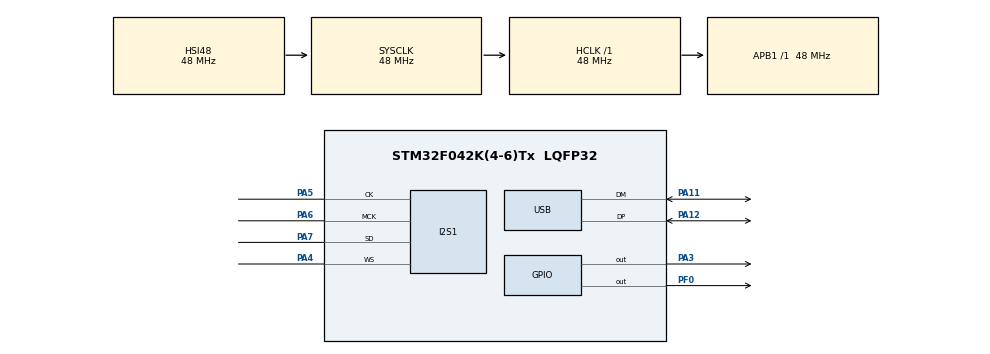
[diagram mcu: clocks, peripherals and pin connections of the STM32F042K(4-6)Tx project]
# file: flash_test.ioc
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I2S1.AudioFreq=I2S_AUDIOFREQ_48K
I2S1.DataFormat=I2S_DATAFORMAT_24B
I2S1.ErrorAudioFreq=-2.34 %
I2S1.FullDuplexMode=I2S_FULLDUPLEXMODE_DISABLE
I2S1.Instance=SPI$Index
I2S1.MCLKOutput=I2S_MCLKOUTPUT_ENABLE
I2S1.RealAudioFreq=46.875 KHz
I2S1.VirtualMode=I2S_MODE_MASTER
Mcu.Family=STM32F0
Mcu.Name=STM32F042K(4-6)Tx
Mcu.Package=LQFP32
PA11.Mode=Device
PA11.Signal=USB_DM
PA12.Mode=Device
PA12.Signal=USB_DP
PA3.Signal=GPIO_Output
PA4.Mode=Half_Duplex_Master
PA4.Signal=I2S1_WS
PA5.Mode=Half_Duplex_Master
PA5.Signal=I2S1_CK
PA6.Mode=Master_Clock_Activated
PA6.Signal=I2S1_MCK
PA7.Mode=Half_Duplex_Master
PA7.Signal=I2S1_SD
PF0-OSC_IN.Signal=GPIO_Output
ProjectManager.HeapSize=0x200
ProjectManager.StackSize=0x400
ProjectManager.TargetToolchain=STM32CubeIDE
RCC.AHBFreq_Value=48000000
RCC.APB1Freq_Value=48000000
RCC.APB1TimFreq_Value=48000000
RCC.HCLKFreq_Value=48000000
RCC.SYSCLKFreq_VALUE=48000000
RCC.SYSCLKSource=RCC_SYSCLKSOURCE_HSI48
board=custom

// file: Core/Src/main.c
/* USER CODE BEGIN Header */
/**
  ******************************************************************************
  * @file           : main.c
  * @brief          : Main program body
  ******************************************************************************
  * @attention
  *
  * Copyright (c) 2022 STMicroelectronics.
  * All rights reserved.
  *
  * This software is licensed under terms that can be found in the LICENSE file
  * in the root directory of this software component.
  * If no LICENSE file comes with this software, it is provided AS-IS.
  *
  ******************************************************************************
  */
/* USER CODE END Header */
#include "main.h"

/* USER CODE BEGIN Includes */
#include "usb_audio.h"
/* USER CODE END Includes */

 I2S_HandleTypeDef hi2s1;

PCD_HandleTypeDef hpcd_USB_FS;

void SystemClock_Config(void);
static void MX_GPIO_Init(void);
static void MX_I2S1_Init(void);
static void MX_USB_PCD_Init(void);

/* USER CODE BEGIN 0 */

/* Private variables ---------------------------------------------------------*/
USBD_HandleTypeDef USBD_Device;
#if USE_AUDIO_TIMER_VOLUME_CTRL
TIM_HandleTypeDef    TimHandle;
/* Prescaler declaration */
uint32_t uwPrescalerValue = 0;
#endif /* USE_AUDIO_TIMER_VOLUME_CTRL */
/* Private function prototypes -----------------------------------------------*/

#if USE_AUDIO_TIMER_VOLUME_CTRL
static HAL_StatusTypeDef Timer_Init(void);
#endif /* USE_AUDIO_TIMER_VOLUME_CTRL */
/* externals  variables -----------------------------------------------*/
extern USBD_AUDIO_InterfaceCallbacksfTypeDef audio_class_interface;

/* USER CODE END 0 */

int main(void)
{

  /* MCU Configuration--------------------------------------------------------*/

  /* Reset of all peripherals, Initializes the Flash interface and the Systick. */
  HAL_Init();

  /* Configure the system clock */
  SystemClock_Config();

  /* Initialize all configured peripherals */
  MX_GPIO_Init();
  MX_I2S1_Init();
  MX_USB_PCD_Init();
  /* USER CODE BEGIN 2 */
  //bring ADC out of reset
  //HAL_GPIO_WritePin(GPIOA, GPIO_PIN_3, GPIO_PIN_SET);
  /* Init Device Library */
  USBD_Init(&USBD_Device, &AUDIO_Desc, 0);

  /* Add Supported Class */
  USBD_RegisterClass(&USBD_Device, USBD_AUDIO_CLASS);

  /* Add Interface callbacks for AUDIO Class */
  USBD_AUDIO_RegisterInterface(&USBD_Device, &audio_class_interface);

  /* Start Device Process */
  USBD_Start(&USBD_Device);
  /* USER CODE END 2 */

  /* Infinite loop */
  while (1)
  {

  }
}

void SystemClock_Config(void)
{
  RCC_OscInitTypeDef RCC_OscInitStruct = {0};
  RCC_ClkInitTypeDef RCC_ClkInitStruct = {0};
  RCC_PeriphCLKInitTypeDef PeriphClkInit = {0};

  /** Initializes the RCC Oscillators according to the specified parameters
  * in the RCC_OscInitTypeDef structure.
  */
  RCC_OscInitStruct.OscillatorType = RCC_OSCILLATORTYPE_HSI48;
  RCC_OscInitStruct.HSI48State = RCC_HSI48_ON;
  RCC_OscInitStruct.PLL.PLLState = RCC_PLL_NONE;
  if (HAL_RCC_OscConfig(&RCC_OscInitStruct) != HAL_OK)
  {
    Error_Handler();
  }

  /** Initializes the CPU, AHB and APB buses clocks
  */
  RCC_ClkInitStruct.ClockType = RCC_CLOCKTYPE_HCLK|RCC_CLOCKTYPE_SYSCLK
                              |RCC_CLOCKTYPE_PCLK1;
  RCC_ClkInitStruct.SYSCLKSource = RCC_SYSCLKSOURCE_HSI48;
  RCC_ClkInitStruct.AHBCLKDivider = RCC_SYSCLK_DIV1;
  RCC_ClkInitStruct.APB1CLKDivider = RCC_HCLK_DIV1;

  if (HAL_RCC_ClockConfig(&RCC_ClkInitStruct, FLASH_LATENCY_1) != HAL_OK)
  {
    Error_Handler();
  }
  PeriphClkInit.PeriphClockSelection = RCC_PERIPHCLK_USB;
  PeriphClkInit.UsbClockSelection = RCC_USBCLKSOURCE_HSI48;

  if (HAL_RCCEx_PeriphCLKConfig(&PeriphClkInit) != HAL_OK)
  {
    Error_Handler();
  }
}

static void MX_I2S1_Init(void)
{

  hi2s1.Instance = SPI1;
  hi2s1.Init.Mode = I2S_MODE_MASTER_TX;
  hi2s1.Init.Standard = I2S_STANDARD_PHILIPS;
  hi2s1.Init.DataFormat = I2S_DATAFORMAT_24B;
  hi2s1.Init.MCLKOutput = I2S_MCLKOUTPUT_ENABLE;
  hi2s1.Init.AudioFreq = I2S_AUDIOFREQ_48K;
  hi2s1.Init.CPOL = I2S_CPOL_LOW;
  if (HAL_I2S_Init(&hi2s1) != HAL_OK)
  {
    Error_Handler();
  }

}

static void MX_USB_PCD_Init(void)
{

  hpcd_USB_FS.Instance = USB;
  hpcd_USB_FS.Init.dev_endpoints = 8;
  hpcd_USB_FS.Init.speed = PCD_SPEED_FULL;
  hpcd_USB_FS.Init.phy_itface = PCD_PHY_EMBEDDED;
  hpcd_USB_FS.Init.low_power_enable = DISABLE;
  hpcd_USB_FS.Init.lpm_enable = DISABLE;
  hpcd_USB_FS.Init.battery_charging_enable = DISABLE;
  if (HAL_PCD_Init(&hpcd_USB_FS) != HAL_OK)
  {
    Error_Handler();
  }

}

static void MX_GPIO_Init(void)
{
  GPIO_InitTypeDef GPIO_InitStruct = {0};

  /* GPIO Ports Clock Enable */
  __HAL_RCC_GPIOF_CLK_ENABLE();
  __HAL_RCC_GPIOA_CLK_ENABLE();

  /*Configure GPIO pin Output Level */
  HAL_GPIO_WritePin(GPIOF, GPIO_PIN_0, GPIO_PIN_RESET);

  /*Configure GPIO pin Output Level */
  HAL_GPIO_WritePin(GPIOA, GPIO_PIN_3, GPIO_PIN_RESET);

  /*Configure GPIO pin : PF0 */
  GPIO_InitStruct.Pin = GPIO_PIN_0;
  GPIO_InitStruct.Mode = GPIO_MODE_OUTPUT_PP;
  GPIO_InitStruct.Pull = GPIO_NOPULL;
  GPIO_InitStruct.Speed = GPIO_SPEED_FREQ_LOW;
  HAL_GPIO_Init(GPIOF, &GPIO_InitStruct);

  /*Configure GPIO pin : PA3 */
  GPIO_InitStruct.Pin = GPIO_PIN_3;
  GPIO_InitStruct.Mode = GPIO_MODE_OUTPUT_PP;
  GPIO_InitStruct.Pull = GPIO_NOPULL;
  GPIO_InitStruct.Speed = GPIO_SPEED_FREQ_LOW;
  HAL_GPIO_Init(GPIOA, &GPIO_InitStruct);

}

void Error_Handler(void)
{
  __disable_irq();
  while (1)
  {
  }
}
